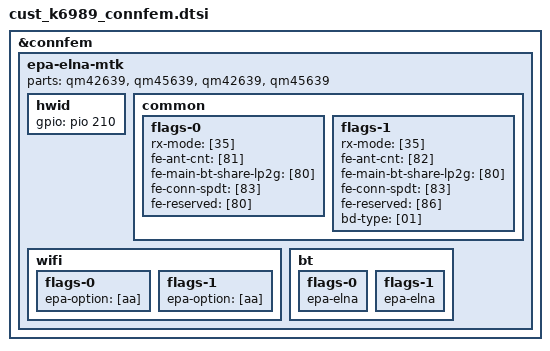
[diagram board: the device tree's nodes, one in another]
// SPDX-License-Identifier: (GPL-2.0 OR MIT)
/*
 * Copyright (C) 2020 MediaTek Inc.
 */
&connfem {
	epa-elna-mtk {
		parts = <&qm42639 &qm45639>,	/* [0] Qorvo eFEM, Phone */
			<&qm42639 &qm45639>;	/* [1] Qorvo eFEM, EVB */

		hwid {
			gpio = <&pio 210 0x0>;
		};

		common {
			flags-0 {
				rx-mode = [35];
				fe-ant-cnt = [81];
				fe-main-bt-share-lp2g = [80];
				fe-conn-spdt = [83];
				fe-reserved = [80];
			};
			flags-1 {
				rx-mode = [35];
				fe-ant-cnt = [82];
				fe-main-bt-share-lp2g = [80];
				fe-conn-spdt = [83];
				fe-reserved = [86];
				bd-type = [01];
			};
		};

		wifi {
			flags-0 {
				epa-option = [aa];
				/* open-loop; */
			};
			flags-1 {
				epa-option = [aa];
				/* open-loop; */
			};
		};

		bt {
			flags-0 {
				/* choose one of: epa-elna / epa / elna / bypass */
				epa-elna;
			};
			flags-1 {
				/* choose one of: epa-elna / epa / elna / bypass */
				epa-elna;
			};
		};
	};
};
